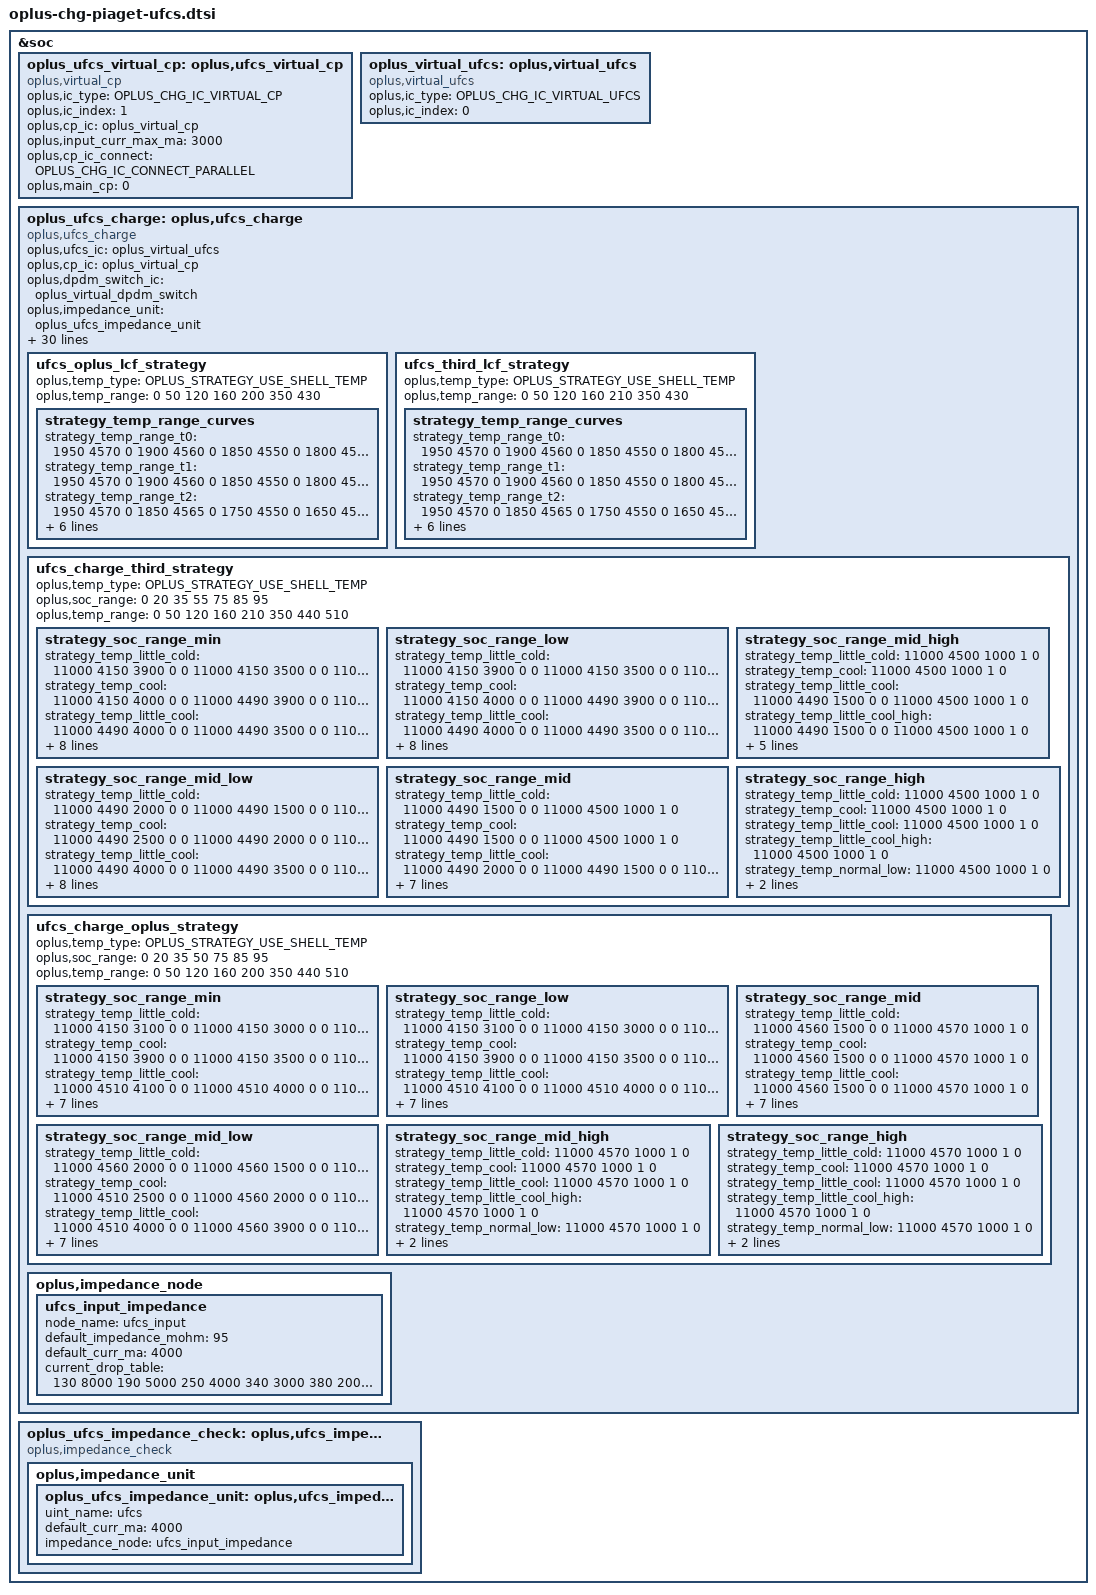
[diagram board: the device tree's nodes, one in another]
//ifdef OPLUS_FEATURE_CHG_BASIC
//BSP.CHG.Basic, 2024/08/03,  Add for charging

#include <dt-bindings/iio/qcom,spmi-adc5-gen3-pmxr2230.h>
#include <dt-bindings/iio/qcom,spmi-adc5-gen3-pmiv0104.h>
#include <dt-bindings/iio/qcom,spmi-adc5-gen3-pmk8550.h>

#include "../oplus-chg-8650.h.dtsi"

&soc {
	oplus_ufcs_virtual_cp: oplus,ufcs_virtual_cp {
		compatible = "oplus,virtual_cp";

		oplus,ic_type = <OPLUS_CHG_IC_VIRTUAL_CP>;
		oplus,ic_index = <1>;

		oplus,cp_ic = <&oplus_virtual_cp>;
		oplus,input_curr_max_ma = <3000>;

		oplus,cp_ic_connect = <OPLUS_CHG_IC_CONNECT_PARALLEL>;
		oplus,main_cp = <0>;
	};

	oplus_virtual_ufcs: oplus,virtual_ufcs {
		compatible = "oplus,virtual_ufcs";

		oplus,ic_type = <OPLUS_CHG_IC_VIRTUAL_UFCS>;
		oplus,ic_index = <0>;
	};

	oplus_ufcs_charge: oplus,ufcs_charge {
		compatible = "oplus,ufcs_charge";
		oplus,ufcs_ic = <&oplus_virtual_ufcs>;
		oplus,cp_ic = <&oplus_virtual_cp>;
		oplus,dpdm_switch_ic = <&oplus_virtual_dpdm_switch>;

		oplus,impedance_unit = <&oplus_ufcs_impedance_unit>;

		oplus,target_vbus_mv = <11000>;
		oplus,curr_max_ma = <4000>;

		oplus,ufcs_warm_allow_vol = <4000>;
		oplus,ufcs_warm_allow_soc = <50>;
		oplus,ufcs_strategy_normal_current = <4000>;//4A
		oplus,ufcs_over_high_or_low_current = <4000>;
		oplus,ufcs_timeout_third = <17614>;
		oplus,ufcs_timeout_oplus = <10800>;
		oplus,ufcs_ibat_over_third = <9000>;
		oplus,ufcs_ibat_over_oplus = <16000>;
		oplus,ufcs_full_cool_sw_vbat = <4500>;
		oplus,ufcs_full_normal_sw_vbat = <4500>;
		oplus,ufcs_full_normal_hw_vbat = <4510>;
		oplus,ufcs_full_ffc_vbat = <4510>;
		oplus,ufcs_full_warm_vbat = <4130>;
		oplus,ufcs_full_cool_sw_vbat_third = <4500>;
		oplus,ufcs_full_normal_sw_vbat_third= <4500>;
		oplus,ufcs_full_normal_hw_vbat_third = <4510>;
		oplus,ufcs_current_change_timeout = <100>;
		oplus,ufcs_strategy_batt_high_temp = <410 420 430 400 410 420>;
		oplus,ufcs_strategy_high_current = <3000 3000 2000 3000 3000 3000>;
		oplus,ufcs_little_cool_high_temp = <200>;
		oplus,curve_strategy_name = "pps_ufcs_curve_v2";
		oplus_spec,ufcs_high_soc = <95>;
		oplus,ufcs_charge_strategy_soc = <0 20 35 50 75 85 95>;
		oplus,ufcs_charge_strategy_temp = <0 50 120 160 350 440 510>;

		ufcs_oplus_lcf_strategy {
			oplus,temp_type = <OPLUS_STRATEGY_USE_SHELL_TEMP>;
			oplus,temp_range = <0 50 120 160 200 350 430>;
			strategy_temp_range_curves {
				strategy_temp_range_t0 =	<1950 4570 0
								 1900 4560 0
								 1850 4550 0
								 1800 4540 0
								 1750 4530 1>;
				strategy_temp_range_t1 =	<1950 4570 0
								 1900 4560 0
								 1850 4550 0
								 1800 4540 0
								 1750 4530 1>;
				strategy_temp_range_t2 =	<1950 4570 0
								 1850 4565 0
								 1750 4550 0
								 1650 4540 0
								 1550 4530 1>;
				strategy_temp_range_t3 =	<1950 4570 0
								 1850 4565 0
								 1750 4550 0
								 1650 4540 0
								 1550 4530 1>;
				strategy_temp_range_t4 =	<1950 4570 0
								 1850 4565 0
								 1750 4550 0
								 1650 4540 0
								 1550 4530 1>;
				strategy_temp_range_t5 =	<1950 4570 0
								 1850 4565 0
								 1750 4550 0
								 1650 4540 0
								 1550 4530 1>;
			};
		};
		ufcs_third_lcf_strategy {
			oplus,temp_type = <OPLUS_STRATEGY_USE_SHELL_TEMP>;
			oplus,temp_range = <0 50 120 160 210 350 430>;
			strategy_temp_range_curves {
				strategy_temp_range_t0 =	<1950 4570 0
								 1900 4560 0
								 1850 4550 0
								 1800 4540 0
								 1750 4530 1>;
				strategy_temp_range_t1 =	<1950 4570 0
								 1900 4560 0
								 1850 4550 0
								 1800 4540 0
								 1750 4530 1>;
				strategy_temp_range_t2 =	<1950 4570 0
								 1850 4565 0
								 1750 4550 0
								 1650 4540 0
								 1550 4530 1>;
				strategy_temp_range_t3 =	<1950 4570 0
								 1850 4565 0
								 1750 4550 0
								 1650 4540 0
								 1550 4530 1>;
				strategy_temp_range_t4 =	<1950 4570 0
								 1850 4565 0
								 1750 4550 0
								 1650 4540 0
								 1550 4530 1>;
				strategy_temp_range_t5 =	<1950 4570 0
								 1850 4565 0
								 1750 4550 0
								 1650 4540 0
								 1550 4530 1>;
			};
		};

		ufcs_charge_third_strategy {
			oplus,temp_type = <OPLUS_STRATEGY_USE_SHELL_TEMP>;
			oplus,soc_range = <0 20 35 55 75 85 95>;
			oplus,temp_range = <0 50 120 160 210 350 440 510>;

			strategy_soc_range_min {
				strategy_temp_little_cold =	<11000 4150 3900 0 0
								11000 4150 3500 0 0
								11000 4490 3200 0 0
								11000 4490 3000 0 0
								11000 4490 2500 0 0
								11000 4490 2000 0 0
								11000 4490 1500 0 0
								11000 4500 1000 1 0>;
				strategy_temp_cool =		<11000 4150 4000 0 0
								11000 4490 3900 0 0
								11000 4490 3500 0 0
								11000 4490 3000 0 0
								11000 4490 2500 0 0
								11000 4490 2000 0 0
								11000 4490 1500 0 0
								11000 4500 1000 1 0>;
				strategy_temp_little_cool =	<11000 4490 4000 0 0
								11000 4490 3500 0 0
								11000 4490 3000 0 0
								11000 4490 2500 0 0
								11000 4490 2000 0 0
								11000 4490 1500 0 0
								11000 4500 1000 1 0>;
				strategy_temp_little_cool_high = <11000 4490 4000 0 0
								11000 4490 3500 0 0
								11000 4490 3000 0 0
								11000 4490 2500 0 0
								11000 4490 2000 0 0
								11000 4490 1500 0 0
								11000 4500 1000 1 0>;
				strategy_temp_normal_low =	<11000 4490 4000 0 0
								11000 4490 3500 0 0
								11000 4490 3000 0 0
								11000 4490 2500 0 0
								11000 4490 2000 0 0
								11000 4490 1500 0 0
								11000 4500 1000 1 0>;
				strategy_temp_normal_high =	<11000 4465 4000 0 0
								11000 4465 3500 0 0
								11000 4465 3000 0 0
								11000 4465 2500 0 0
								11000 4465 2000 0 0
								11000 4465 1500 0 0
								11000 4475 1000 1 0>;
				strategy_temp_warm =		<11000 4120 1800 0 0
								11000 4120 1500 0 0
								11000 4130 1000 1 0>;
			};
			strategy_soc_range_low {
				strategy_temp_little_cold =	<11000 4150 3900 0 0
								11000 4150 3500 0 0
								11000 4490 3200 0 0
								11000 4490 3000 0 0
								11000 4490 2500 0 0
								11000 4490 2000 0 0
								11000 4490 1500 0 0
								11000 4500 1000 1 0>;
				strategy_temp_cool =		<11000 4150 4000 0 0
								11000 4490 3900 0 0
								11000 4490 3500 0 0
								11000 4490 3000 0 0
								11000 4490 2500 0 0
								11000 4490 2000 0 0
								11000 4490 1500 0 0
								11000 4500 1000 1 0>;
				strategy_temp_little_cool =	<11000 4490 4000 0 0
								11000 4490 3500 0 0
								11000 4490 3000 0 0
								11000 4490 2500 0 0
								11000 4490 2000 0 0
								11000 4490 1500 0 0
								11000 4500 1000 1 0>;
				strategy_temp_little_cool_high = <11000 4490 4000 0 0
								11000 4490 3500 0 0
								11000 4490 3000 0 0
								11000 4490 2500 0 0
								11000 4490 2000 0 0
								11000 4490 1500 0 0
								11000 4500 1000 1 0>;
				strategy_temp_normal_low =	<11000 4490 4000 0 0
								11000 4490 3500 0 0
								11000 4490 3000 0 0
								11000 4490 2500 0 0
								11000 4490 2000 0 0
								11000 4490 1500 0 0
								11000 4500 1000 1 0>;
				strategy_temp_normal_high =	<11000 4465 4000 0 0
								11000 4465 3500 0 0
								11000 4465 3000 0 0
								11000 4465 2500 0 0
								11000 4465 2000 0 0
								11000 4465 1500 0 0
								11000 4475 1000 1 0>;
				strategy_temp_warm =		<11000 4120 1800 0 0
								11000 4120 1500 0 0
								11000 4130 1000 1 0>;
			};
			strategy_soc_range_mid_low {
				strategy_temp_little_cold =	<11000 4490 2000 0 0
								11000 4490 1500 0 0
								11000 4500 1000 1 0>;
				strategy_temp_cool =		<11000 4490 2500 0 0
								11000 4490 2000 0 0
								11000 4490 1500 0 0
								11000 4500 1000 1 0>;
				strategy_temp_little_cool =	<11000 4490 4000 0 0
								11000 4490 3500 0 0
								11000 4490 3000 0 0
								11000 4490 2500 0 0
								11000 4490 2000 0 0
								11000 4490 1500 0 0
								11000 4500 1000 1 0>;
				strategy_temp_little_cool_high = <11000 4490 4000 0 0
								11000 4490 3500 0 0
								11000 4490 3000 0 0
								11000 4490 2500 0 0
								11000 4490 2000 0 0
								11000 4490 1500 0 0
								11000 4500 1000 1 0>;
				strategy_temp_normal_low =	<11000 4490 4000 0 0
								11000 4490 3500 0 0
								11000 4490 3000 0 0
								11000 4490 2500 0 0
								11000 4490 2000 0 0
								11000 4490 1500 0 0
								11000 4500 1000 1 0>;
				strategy_temp_normal_high =	<11000 4465 4000 0 0
								11000 4465 3500 0 0
								11000 4465 3000 0 0
								11000 4465 2500 0 0
								11000 4465 2000 0 0
								11000 4465 1500 0 0
								11000 4475 1000 1 0>;
				strategy_temp_warm =		<11000 4120 1800 0 0
								11000 4120 1500 0 0
								11000 4130 1000 1 0>;
			};
			strategy_soc_range_mid {
				strategy_temp_little_cold =	<11000 4490 1500 0 0
								11000 4500 1000 1 0>;
				strategy_temp_cool =		<11000 4490 1500 0 0
								11000 4500 1000 1 0>;
				strategy_temp_little_cool =	<11000 4490 2000 0 0
								11000 4490 1500 0 0
								11000 4500 1000 1 0>;
				strategy_temp_little_cool_high = <11000 4490 2000 0 0
								11000 4490 1500 0 0
								11000 4500 1000 1 0>;
				strategy_temp_normal_low =	<11000 4490 2000 0 0
								11000 4490 1500 0 0
								11000 4500 1000 1 0>;
				strategy_temp_normal_high =	<11000 4465 2500 0 0
								11000 4465 2000 0 0
								11000 4465 1500 0 0
								11000 4475 1000 1 0>;
				strategy_temp_warm =		<11000 4130 1000 1 0>;
			};
			strategy_soc_range_mid_high {
				strategy_temp_little_cold =	<11000 4500 1000 1 0>;
				strategy_temp_cool =		<11000 4500 1000 1 0>;
				strategy_temp_little_cool =	<11000 4490 1500 0 0
								11000 4500 1000 1 0>;
				strategy_temp_little_cool_high = <11000 4490 1500 0 0
								11000 4500 1000 1 0>;
				strategy_temp_normal_low =	<11000 4490 1500 0 0
								11000 4500 1000 1 0>;
				strategy_temp_normal_high =	<11000 4465 1500 0 0
								11000 4475 1000 1 0>;
				strategy_temp_warm =		<11000 4130 1000 1 0>;
			};
			strategy_soc_range_high {
				strategy_temp_little_cold =	<11000 4500 1000 1 0>;
				strategy_temp_cool =		<11000 4500 1000 1 0>;
				strategy_temp_little_cool =	<11000 4500 1000 1 0>;
				strategy_temp_little_cool_high = <11000 4500 1000 1 0>;
				strategy_temp_normal_low =	<11000 4500 1000 1 0>;
				strategy_temp_normal_high =	<11000 4475 1000 1 0>;
				strategy_temp_warm =		<11000 4130 1000 1 0>;
			};
		};

		ufcs_charge_oplus_strategy {
			oplus,temp_type = <OPLUS_STRATEGY_USE_SHELL_TEMP>;
			oplus,soc_range = <0 20 35 50 75 85 95>;
			oplus,temp_range = <0 50 120 160 200 350 440 510>;
			strategy_soc_range_min {
				strategy_temp_little_cold =	<11000 4150 3100 0 0
								11000 4150 3000 0 0
								11000 4510 2600 0 0
								11000 4510 2500 0 0
								11000 4560 2000 0 0
								11000 4560 1500 0 0
								11000 4570 1000 1 0>;
				strategy_temp_cool =		<11000 4150 3900 0 0
								11000 4150 3500 0 0
								11000 4510 3100 0 0
								11000 4510 3000 0 0
								11000 4510 2500 0 0
								11000 4560 2000 0 0
								11000 4560 1500 0 0
								11000 4570 1000 1 0>;
				strategy_temp_little_cool =	<11000 4510 4100 0 0
								11000 4510 4000 0 0
								11000 4560 3900 0 0
								11000 4560 3500 0 0
								11000 4560 3000 0 0
								11000 4560 2500 0 0
								11000 4560 2000 0 0
								11000 4570 1000 1 0>;
				strategy_temp_little_cool_high = <11000 4510 4100 0 0
								11000 4510 4000 0 0
								11000 4560 3900 0 0
								11000 4560 3500 0 0
								11000 4560 3000 0 0
								11000 4560 2500 0 0
								11000 4560 2000 0 0
								11000 4570 1000 1 0>;
				strategy_temp_normal_low =	<11000 4510 4100 0 0
								11000 4510 4000 0 0
								11000 4560 3900 0 0
								11000 4560 3500 0 0
								11000 4560 3000 0 0
								11000 4560 2500 0 0
								11000 4560 2000 0 0
								11000 4570 1000 1 0>;
				strategy_temp_normal_high =	<11000 4510 4100 0 0
								11000 4510 4000 0 0
								11000 4560 3900 0 0
								11000 4560 3500 0 0
								11000 4560 3000 0 0
								11000 4560 2500 0 0
								11000 4560 2000 0 0
								11000 4570 1000 1 0>;
				strategy_temp_warm =		<11000 4130 1000 1 0>;
			};
			strategy_soc_range_low {
				strategy_temp_little_cold =	<11000 4150 3100 0 0
								11000 4150 3000 0 0
								11000 4510 2600 0 0
								11000 4510 2500 0 0
								11000 4560 2000 0 0
								11000 4560 1500 0 0
								11000 4570 1000 1 0>;
				strategy_temp_cool =		<11000 4150 3900 0 0
								11000 4150 3500 0 0
								11000 4510 3100 0 0
								11000 4510 3000 0 0
								11000 4510 2500 0 0
								11000 4560 2000 0 0
								11000 4560 1500 0 0
								11000 4570 1000 1 0>;
				strategy_temp_little_cool =	<11000 4510 4100 0 0
								11000 4510 4000 0 0
								11000 4560 3900 0 0
								11000 4560 3500 0 0
								11000 4560 3000 0 0
								11000 4560 2500 0 0
								11000 4560 2000 0 0
								11000 4570 1000 1 0>;
				strategy_temp_little_cool_high = <11000 4510 4100 0 0
								11000 4510 4000 0 0
								11000 4560 3900 0 0
								11000 4560 3500 0 0
								11000 4560 3000 0 0
								11000 4560 2500 0 0
								11000 4560 2000 0 0
								11000 4570 1000 1 0>;
				strategy_temp_normal_low =	<11000 4510 4100 0 0
								11000 4510 4000 0 0
								11000 4560 3900 0 0
								11000 4560 3500 0 0
								11000 4560 3000 0 0
								11000 4560 2500 0 0
								11000 4560 2000 0 0
								11000 4570 1000 1 0>;
				strategy_temp_normal_high =	<11000 4510 4100 0 0
								11000 4510 4000 0 0
								11000 4560 3900 0 0
								11000 4560 3500 0 0
								11000 4560 3000 0 0
								11000 4560 2500 0 0
								11000 4560 2000 0 0
								11000 4570 1000 1 0>;
				strategy_temp_warm =		<11000 4130 1000 1 0>;
			};
			strategy_soc_range_mid_low {
				strategy_temp_little_cold =	<11000 4560 2000 0 0
								11000 4560 1500 0 0
								11000 4570 1000 1 0>;
				strategy_temp_cool =		<11000 4510 2500 0 0
								11000 4560 2000 0 0
								11000 4560 1500 0 0
								11000 4570 1000 1 0>;
				strategy_temp_little_cool =	<11000 4510 4000 0 0
								11000 4560 3900 0 0
								11000 4560 3500 0 0
								11000 4560 3000 0 0
								11000 4560 2500 0 0
								11000 4560 2000 0 0
								11000 4570 1000 1 0>;
				strategy_temp_little_cool_high = <11000 4510 4000 0 0
								11000 4560 3900 0 0
								11000 4560 3500 0 0
								11000 4560 3000 0 0
								11000 4560 2500 0 0
								11000 4560 2000 0 0
								11000 4570 1000 1 0>;
				strategy_temp_normal_low =	<11000 4510 4100 0 0
								11000 4510 4000 0 0
								11000 4560 3900 0 0
								11000 4560 3500 0 0
								11000 4560 3000 0 0
								11000 4560 2500 0 0
								11000 4560 2000 0 0
								11000 4570 1000 1 0>;
				strategy_temp_normal_high =	<11000 4510 4100 0 0
								11000 4510 4000 0 0
								11000 4560 3900 0 0
								11000 4560 3500 0 0
								11000 4560 3000 0 0
								11000 4560 2500 0 0
								11000 4560 2000 0 0
								11000 4570 1000 1 0>;
				strategy_temp_warm =		<11000 4130 1000 1 0>;
			};
			strategy_soc_range_mid {
				strategy_temp_little_cold =	<11000 4560 1500 0 0
								11000 4570 1000 1 0>;
				strategy_temp_cool =		<11000 4560 1500 0 0
								11000 4570 1000 1 0>;
				strategy_temp_little_cool =	<11000 4560 1500 0 0
								11000 4570 1000 1 0>;
				strategy_temp_little_cool_high = <11000 4560 1500 0 0
								11000 4570 1000 1 0>;
				strategy_temp_normal_low =	<11000 4560 2500 0 0
								11000 4570 1000 1 0>;
				strategy_temp_normal_high =	<11000 4560 3000 0 0
								11000 4560 2500 0 0
								11000 4570 1000 1 0>;
				strategy_temp_warm =		<11000 4130 1000 1 0>;
			};
			strategy_soc_range_mid_high {
				strategy_temp_little_cold =	<11000 4570 1000 1 0>;
				strategy_temp_cool =		<11000 4570 1000 1 0>;
				strategy_temp_little_cool =	<11000 4570 1000 1 0>;
				strategy_temp_little_cool_high = <11000 4570 1000 1 0>;
				strategy_temp_normal_low =	<11000 4570 1000 1 0>;
				strategy_temp_normal_high =	<11000 4570 1000 1 0>;
				strategy_temp_warm =		<11000 4130 1000 1 0>;
			};
			strategy_soc_range_high {
				strategy_temp_little_cold =	<11000 4570 1000 1 0>;
				strategy_temp_cool =		<11000 4570 1000 1 0>;
				strategy_temp_little_cool =	<11000 4570 1000 1 0>;
				strategy_temp_little_cool_high = <11000 4570 1000 1 0>;
				strategy_temp_normal_low =	<11000 4570 1000 1 0>;
				strategy_temp_normal_high =	<11000 4570 1000 1 0>;
				strategy_temp_warm =		<11000 4130 1000 1 0>;
			};
		};

		oplus,impedance_node {
			ufcs_input_impedance: ufcs_input_impedance {
				node_name = "ufcs_input";
				default_impedance_mohm = <95>;
				default_curr_ma = <4000>;
				current_drop_table = <
					130  8000
					190  5000
					250  4000
					340  3000
					380  2000
					480  0
				>;
			};
		};
	};

	oplus_ufcs_impedance_check: oplus,ufcs_impedance_check {
		compatible = "oplus,impedance_check";

		oplus,impedance_unit {
			oplus_ufcs_impedance_unit: oplus,ufcs_impedance_unit {
				uint_name = "ufcs";
				default_curr_ma = <4000>;
				impedance_node = <&ufcs_input_impedance>;
			};
		};
	};
};
